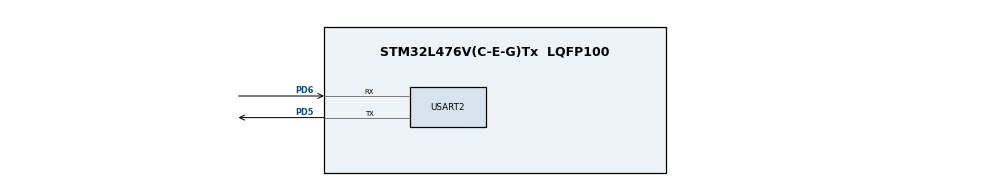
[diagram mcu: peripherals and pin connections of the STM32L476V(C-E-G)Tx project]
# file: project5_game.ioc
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FREERTOS.Tasks01=defaultTask,24,128,StartDefaultTask,Default,NULL,Dynamic,NULL,NULL
Mcu.Family=STM32L4
Mcu.Name=STM32L476V(C-E-G)Tx
Mcu.Package=LQFP100
NVIC.PriorityGroup=NVIC_PRIORITYGROUP_4
NVIC.TIM1_UP_TIM16_IRQn=true\:0\:0\:false\:false\:true\:false\:false\:true
NVIC.TimeBase=TIM1_UP_TIM16_IRQn
NVIC.TimeBaseIP=TIM1
PA13\ (JTMS-SWDIO).Mode=Serial_Wire
PA13\ (JTMS-SWDIO).Signal=SYS_JTMS-SWDIO
PA14\ (JTCK-SWCLK).Mode=Serial_Wire
PA14\ (JTCK-SWCLK).Signal=SYS_JTCK-SWCLK
PD5.Mode=Asynchronous
PD5.Signal=USART2_TX
PD6.Mode=Asynchronous
PD6.Signal=USART2_RX
ProjectManager.HeapSize=0x200
ProjectManager.StackSize=0x400
ProjectManager.TargetToolchain=STM32CubeIDE
RCC.HSE_VALUE=8000000
RCC.HSI_VALUE=16000000
RCC.LSE_VALUE=32768
RCC.MSI_VALUE=4000000
RCC.VCOOutputFreq_Value=32000000
USART2.VirtualMode-Asynchronous=VM_ASYNC
VP_FREERTOS_VS_CMSIS_V2.Mode=CMSIS_V2
VP_SYS_VS_tim1.Mode=TIM1
board=custom

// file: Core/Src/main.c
/* USER CODE BEGIN Header */
/**
  ******************************************************************************
  * @file           : main.c
  * @brief          : Main program body
  ******************************************************************************
  * @attention
  *
  * <h2><center>&copy; Copyright (c) 2020 STMicroelectronics.
  * All rights reserved.</center></h2>
  *
  * This software component is licensed by ST under BSD 3-Clause license,
  * the "License"; You may not use this file except in compliance with the
  * License. You may obtain a copy of the License at:
  *                        opensource.org/licenses/BSD-3-Clause
  *
  ******************************************************************************
  */
/* USER CODE END Header */

#include "main.h"
#include "cmsis_os.h"

/* USER CODE BEGIN Includes */
#include <stdio.h>
#include <string.h>

/* USER CODE END Includes */

UART_HandleTypeDef huart2;

/* Definitions for defaultTask */
osThreadId_t defaultTaskHandle;
const osThreadAttr_t defaultTask_attributes = {
  .name = "defaultTask",
  .priority = (osPriority_t) osPriorityNormal,
  .stack_size = 128 * 4
};

void SystemClock_Config(void);
static void MX_GPIO_Init(void);
static void MX_USART2_UART_Init(void);
void StartDefaultTask(void *argument);

int main(void)
{

  /* MCU Configuration--------------------------------------------------------*/

  /* Reset of all peripherals, Initializes the Flash interface and the Systick. */
  HAL_Init();

  /* Configure the system clock */
  SystemClock_Config();

  /* Initialize all configured peripherals */
  MX_GPIO_Init();
  MX_USART2_UART_Init();

  /* Init scheduler */
  osKernelInitialize();

  /* Create the thread(s) */
  /* creation of defaultTask */
  defaultTaskHandle = osThreadNew(StartDefaultTask, NULL, &defaultTask_attributes);

  /* Start scheduler */
  osKernelStart();

  /* We should never get here as control is now taken by the scheduler */
  /* Infinite loop */
  while (1)
  {

  }
}

void SystemClock_Config(void)
{
  RCC_OscInitTypeDef RCC_OscInitStruct = {0};
  RCC_ClkInitTypeDef RCC_ClkInitStruct = {0};
  RCC_PeriphCLKInitTypeDef PeriphClkInit = {0};

  /** Initializes the CPU, AHB and APB busses clocks
  */
  RCC_OscInitStruct.OscillatorType = RCC_OSCILLATORTYPE_MSI;
  RCC_OscInitStruct.MSIState = RCC_MSI_ON;
  RCC_OscInitStruct.MSICalibrationValue = 0;
  RCC_OscInitStruct.MSIClockRange = RCC_MSIRANGE_6;
  RCC_OscInitStruct.PLL.PLLState = RCC_PLL_NONE;
  if (HAL_RCC_OscConfig(&RCC_OscInitStruct) != HAL_OK)
  {
    Error_Handler();
  }
  /** Initializes the CPU, AHB and APB busses clocks
  */
  RCC_ClkInitStruct.ClockType = RCC_CLOCKTYPE_HCLK|RCC_CLOCKTYPE_SYSCLK
                              |RCC_CLOCKTYPE_PCLK1|RCC_CLOCKTYPE_PCLK2;
  RCC_ClkInitStruct.SYSCLKSource = RCC_SYSCLKSOURCE_MSI;
  RCC_ClkInitStruct.AHBCLKDivider = RCC_SYSCLK_DIV1;
  RCC_ClkInitStruct.APB1CLKDivider = RCC_HCLK_DIV1;
  RCC_ClkInitStruct.APB2CLKDivider = RCC_HCLK_DIV1;

  if (HAL_RCC_ClockConfig(&RCC_ClkInitStruct, FLASH_LATENCY_0) != HAL_OK)
  {
    Error_Handler();
  }
  PeriphClkInit.PeriphClockSelection = RCC_PERIPHCLK_USART2;
  PeriphClkInit.Usart2ClockSelection = RCC_USART2CLKSOURCE_PCLK1;
  if (HAL_RCCEx_PeriphCLKConfig(&PeriphClkInit) != HAL_OK)
  {
    Error_Handler();
  }
  /** Configure the main internal regulator output voltage
  */
  if (HAL_PWREx_ControlVoltageScaling(PWR_REGULATOR_VOLTAGE_SCALE1) != HAL_OK)
  {
    Error_Handler();
  }
}

static void MX_USART2_UART_Init(void)
{

  huart2.Instance = USART2;
  huart2.Init.BaudRate = 115200;
  huart2.Init.WordLength = UART_WORDLENGTH_8B;
  huart2.Init.StopBits = UART_STOPBITS_1;
  huart2.Init.Parity = UART_PARITY_NONE;
  huart2.Init.Mode = UART_MODE_TX_RX;
  huart2.Init.HwFlowCtl = UART_HWCONTROL_NONE;
  huart2.Init.OverSampling = UART_OVERSAMPLING_16;
  huart2.Init.OneBitSampling = UART_ONE_BIT_SAMPLE_DISABLE;
  huart2.AdvancedInit.AdvFeatureInit = UART_ADVFEATURE_NO_INIT;
  if (HAL_UART_Init(&huart2) != HAL_OK)
  {
    Error_Handler();
  }

}

static void MX_GPIO_Init(void)
{

  /* GPIO Ports Clock Enable */
  __HAL_RCC_GPIOA_CLK_ENABLE();
  __HAL_RCC_GPIOD_CLK_ENABLE();

}

void StartDefaultTask(void *argument)
{
  /* USER CODE BEGIN 5 */
	uint8_t buffer[64];
  /* Infinite loop */
  for(;;)
  {
	  sprintf(buffer,"Hello World\r\n");
	  HAL_UART_Transmit(&huart2, buffer, strlen((char*)buffer), HAL_MAX_DELAY);
    osDelay(1);
  }
  /* USER CODE END 5 */
}

 /**
  * @brief  Period elapsed callback in non blocking mode
  * @note   This function is called  when TIM1 interrupt took place, inside
  * HAL_TIM_IRQHandler(). It makes a direct call to HAL_IncTick() to increment
  * a global variable "uwTick" used as application time base.
  * @param  htim : TIM handle
  * @retval None
  */
void HAL_TIM_PeriodElapsedCallback(TIM_HandleTypeDef *htim)
{
  if (htim->Instance == TIM1) {
    HAL_IncTick();
  }
}

void Error_Handler(void)
{
}

/************************ (C) COPYRIGHT STMicroelectronics *****END OF FILE****/
